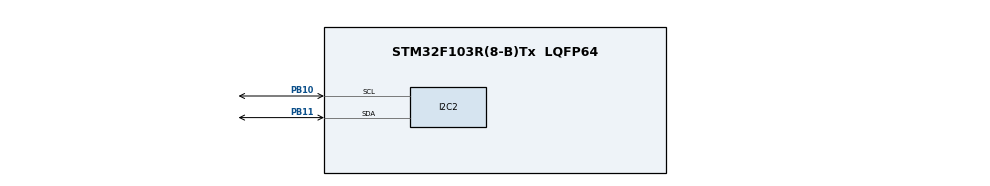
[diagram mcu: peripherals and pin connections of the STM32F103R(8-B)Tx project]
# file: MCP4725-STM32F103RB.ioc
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I2C2.I2C_Mode=I2C_Fast
Mcu.Family=STM32F1
Mcu.Name=STM32F103R(8-B)Tx
Mcu.Package=LQFP64
NVIC.PriorityGroup=NVIC_PRIORITYGROUP_4
NVIC.TIM1_UP_IRQn=true\:0\:0\:false\:false\:true\:true\:true
PA13.Mode=Serial_Wire
PA13.Signal=SYS_JTMS-SWDIO
PA14.Mode=Serial_Wire
PA14.Signal=SYS_JTCK-SWCLK
PB10.Mode=I2C
PB10.Signal=I2C2_SCL
PB11.Mode=I2C
PB11.Signal=I2C2_SDA
PD0-OSC_IN.Mode=HSE-External-Oscillator
PD0-OSC_IN.Signal=RCC_OSC_IN
PD1-OSC_OUT.Mode=HSE-External-Oscillator
PD1-OSC_OUT.Signal=RCC_OSC_OUT
ProjectManager.HeapSize=0x200
ProjectManager.StackSize=0x400
ProjectManager.TargetToolchain=STM32CubeIDE
RCC.APB1Freq_Value=8000000
RCC.APB2Freq_Value=8000000
TIM1.Period=200-1
TIM1.Prescaler=100-1
VP_TIM1_VS_ClockSourceINT.Mode=Internal
board=custom

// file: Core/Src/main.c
/* USER CODE BEGIN Header */
/**
  ******************************************************************************
  * @file           : main.c
  * @brief          : Main program body
  ******************************************************************************
  * @attention
  *
  * Copyright (c) 2022 STMicroelectronics.
  * All rights reserved.
  *
  * This software is licensed under terms that can be found in the LICENSE file
  * in the root directory of this software component.
  * If no LICENSE file comes with this software, it is provided AS-IS.
  *
  ******************************************************************************
  */
/* USER CODE END Header */
#include "main.h"

/* USER CODE BEGIN Includes */
#include "mcp4725.h"
#include "math.h"
/* USER CODE END Includes */

I2C_HandleTypeDef hi2c2;

TIM_HandleTypeDef htim1;

void SystemClock_Config(void);
static void MX_GPIO_Init(void);
static void MX_I2C2_Init(void);
static void MX_TIM1_Init(void);
/* USER CODE BEGIN PFP */
uint8_t setValue(uint16_t value);
/* USER CODE END PFP */

/* USER CODE BEGIN 0 */

	// First, create an MCP4725 object:
	MCP4725 myMCP4725;

	uint32_t micro_seconds = 0;

/* USER CODE END 0 */

int main(void)
{

  /* MCU Configuration--------------------------------------------------------*/

  /* Reset of all peripherals, Initializes the Flash interface and the Systick. */
  HAL_Init();

  /* Configure the system clock */
  SystemClock_Config();

  /* Initialize all configured peripherals */
  MX_GPIO_Init();
  MX_I2C2_Init();
  MX_TIM1_Init();
  /* USER CODE BEGIN 2 */
  // mcp init
  myMCP4725 = MCP4725_init(&hi2c2, MCP4725A0_A00, 3.30);

  HAL_TIM_Base_Start_IT(&htim1);

  /* USER CODE END 2 */

  /* Infinite loop */
  while (1)
  {

  }
}

void SystemClock_Config(void)
{
  RCC_OscInitTypeDef RCC_OscInitStruct = {0};
  RCC_ClkInitTypeDef RCC_ClkInitStruct = {0};

  /** Initializes the RCC Oscillators according to the specified parameters
  * in the RCC_OscInitTypeDef structure.
  */
  RCC_OscInitStruct.OscillatorType = RCC_OSCILLATORTYPE_HSI;
  RCC_OscInitStruct.HSIState = RCC_HSI_ON;
  RCC_OscInitStruct.HSICalibrationValue = RCC_HSICALIBRATION_DEFAULT;
  RCC_OscInitStruct.PLL.PLLState = RCC_PLL_NONE;
  if (HAL_RCC_OscConfig(&RCC_OscInitStruct) != HAL_OK)
  {
    Error_Handler();
  }
  /** Initializes the CPU, AHB and APB buses clocks
  */
  RCC_ClkInitStruct.ClockType = RCC_CLOCKTYPE_HCLK|RCC_CLOCKTYPE_SYSCLK
                              |RCC_CLOCKTYPE_PCLK1|RCC_CLOCKTYPE_PCLK2;
  RCC_ClkInitStruct.SYSCLKSource = RCC_SYSCLKSOURCE_HSI;
  RCC_ClkInitStruct.AHBCLKDivider = RCC_SYSCLK_DIV1;
  RCC_ClkInitStruct.APB1CLKDivider = RCC_HCLK_DIV1;
  RCC_ClkInitStruct.APB2CLKDivider = RCC_HCLK_DIV1;

  if (HAL_RCC_ClockConfig(&RCC_ClkInitStruct, FLASH_LATENCY_0) != HAL_OK)
  {
    Error_Handler();
  }
}

static void MX_I2C2_Init(void)
{

  hi2c2.Instance = I2C2;
  hi2c2.Init.ClockSpeed = 400000;
  hi2c2.Init.DutyCycle = I2C_DUTYCYCLE_2;
  hi2c2.Init.OwnAddress1 = 0;
  hi2c2.Init.AddressingMode = I2C_ADDRESSINGMODE_7BIT;
  hi2c2.Init.DualAddressMode = I2C_DUALADDRESS_DISABLE;
  hi2c2.Init.OwnAddress2 = 0;
  hi2c2.Init.GeneralCallMode = I2C_GENERALCALL_DISABLE;
  hi2c2.Init.NoStretchMode = I2C_NOSTRETCH_DISABLE;
  if (HAL_I2C_Init(&hi2c2) != HAL_OK)
  {
    Error_Handler();
  }

}

static void MX_TIM1_Init(void)
{

  TIM_ClockConfigTypeDef sClockSourceConfig = {0};
  TIM_MasterConfigTypeDef sMasterConfig = {0};

  htim1.Instance = TIM1;
  htim1.Init.Prescaler = 100-1;
  htim1.Init.CounterMode = TIM_COUNTERMODE_UP;
  htim1.Init.Period = 200-1;
  htim1.Init.ClockDivision = TIM_CLOCKDIVISION_DIV1;
  htim1.Init.RepetitionCounter = 0;
  htim1.Init.AutoReloadPreload = TIM_AUTORELOAD_PRELOAD_DISABLE;
  if (HAL_TIM_Base_Init(&htim1) != HAL_OK)
  {
    Error_Handler();
  }
  sClockSourceConfig.ClockSource = TIM_CLOCKSOURCE_INTERNAL;
  if (HAL_TIM_ConfigClockSource(&htim1, &sClockSourceConfig) != HAL_OK)
  {
    Error_Handler();
  }
  sMasterConfig.MasterOutputTrigger = TIM_TRGO_RESET;
  sMasterConfig.MasterSlaveMode = TIM_MASTERSLAVEMODE_DISABLE;
  if (HAL_TIMEx_MasterConfigSynchronization(&htim1, &sMasterConfig) != HAL_OK)
  {
    Error_Handler();
  }

}

static void MX_GPIO_Init(void)
{

  /* GPIO Ports Clock Enable */
  __HAL_RCC_GPIOD_CLK_ENABLE();
  __HAL_RCC_GPIOB_CLK_ENABLE();
  __HAL_RCC_GPIOA_CLK_ENABLE();

}

/* USER CODE BEGIN 4 */
void HAL_TIM_PeriodElapsedCallback(TIM_HandleTypeDef *htim)
{
	setValue((uint16_t)( sinf( 2 * 3.141592 * 1 * (micro_seconds++) / 10000.0 ) * 2047 + 2048));
}

uint8_t setValue(uint16_t value){
	return MCP4725_setValue(&myMCP4725, value, MCP4725_FAST_MODE, MCP4725_PD_OFF);
}
/* USER CODE END 4 */

void Error_Handler(void)
{
  __disable_irq();
  while (1)
  {
  }
}
